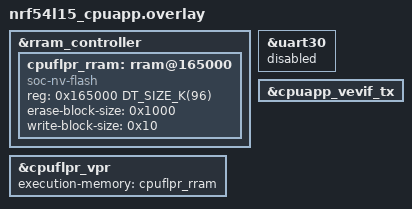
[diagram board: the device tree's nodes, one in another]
/*
 * Copyright (c) 2024 Nordic Semiconductor
 * SPDX-License-Identifier: Apache-2.0
 */

&rram_controller {
	cpuflpr_rram: rram@165000 {
		compatible = "soc-nv-flash";
		reg = <0x165000 DT_SIZE_K(96)>;
		ranges = <0x0 0x165000 DT_SIZE_K(96)>;
		erase-block-size = <0x1000>;
		write-block-size = <0x10>;
		#address-cells = <1>;
		#size-cells = <1>;
	};
};

&uart30 {
	status = "reserved";
};

&cpuflpr_vpr {
	execution-memory = <&cpuflpr_rram>;
};

&cpuapp_vevif_tx {
	status = "okay";
};
